# ATSAMS70N19 register map
Vendor: Microchip Technology; File version: 0
CPU: CM7 r1p1, little endian, no MPU, no FPU, 0x3 interrupt priority bits, 0x0 interrupts
Registers are 32-bit, read-write, reset 0x0 unless marked. A register's access mark holds for its fields unless they carry their own. Offsets are from the block's base; [hi:lo] are bit positions; {n}, {i} and the like mark numbered series; 'fields as' and 'values as' point back to an identical list.

## AFEC0 — Analog Front-End Controller
Base 0x4003C000; register names take the prefix AFEC_
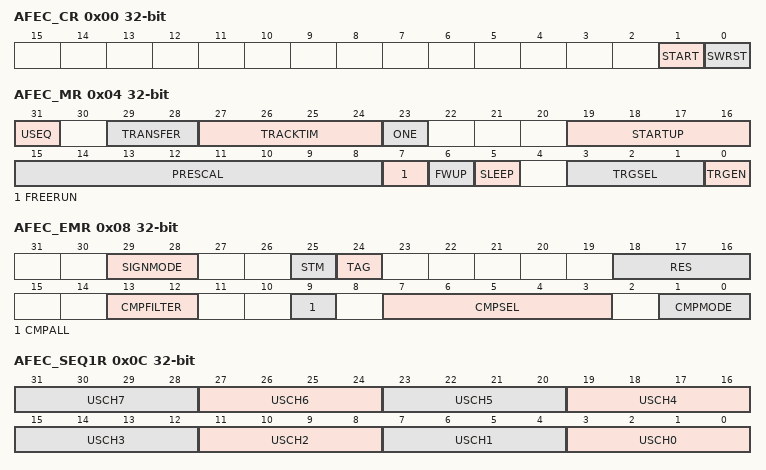
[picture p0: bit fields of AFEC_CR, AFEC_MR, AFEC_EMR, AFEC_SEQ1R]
0x00 AFEC_CR wo — AFEC Control Register
  [1] START — Start Conversion
  [0] SWRST — Software Reset
0x04 AFEC_MR — AFEC Mode Register
  [31] USEQ — User Sequence Enable
    0=NUM_ORDER (Normal mode: The controller converts channels in a simple numeric order.); 1=REG_ORDER (User Sequence mode: The sequence respects what is defined in AFEC_SEQ1R and AFEC_SEQ1R.)
  [29:28] TRANSFER — Transfer Period
  [27:24] TRACKTIM — Tracking Time
  [23] ONE
  [19:16] STARTUP — Start-up Time
    0=SUT0 (0 periods of AFE clock); 1=SUT8 (8 periods of AFE clock); 2=SUT16 (16 periods of AFE clock); 3=SUT24 (24 periods of AFE clock); 4=SUT64 (64 periods of AFE clock); 5=SUT80 (80 periods of AFE clock); 6=SUT96 (96 periods of AFE clock); 7=SUT112 (112 periods of AFE clock); 8=SUT512 (512 periods of AFE clock); 9=SUT576 (576 periods of AFE clock); 10=SUT640 (640 periods of AFE clock); 11=SUT704 (704 periods of AFE clock); 12=SUT768 (768 periods of AFE clock); 13=SUT832 (832 periods of AFE clock); 14=SUT896 (896 periods of AFE clock); 15=SUT960 (960 periods of AFE clock)
  [15:8] PRESCAL — Prescaler Rate Selection
  [7] FREERUN — Free Run Mode
    0=OFF (Normal mode); 1=ON (Free Run mode: Never wait for any trigger.)
  [6] FWUP — Fast Wake-up
    0=OFF (Normal Sleep mode: The sleep mode is defined by the SLEEP bit.); 1=ON (Fast wake-up Sleep mode: The voltage reference is ON between conversions and AFE is OFF.)
  [5] SLEEP — Sleep Mode
    0=NORMAL (Normal mode: The AFE and reference voltage circuitry are kept ON between conversions.); 1=SLEEP (Sleep mode: The AFE and reference voltage circuitry are OFF between conversions.)
  [3:1] TRGSEL — Trigger Selection
    0=AFEC_TRIG0 (AFE0_ADTRG for AFEC0 / AFE1_ADTRG for AFEC1); 1=AFEC_TRIG1 (TIOA Output of the Timer Counter Channel 0 for AFEC0/TIOA Output of the Timer Counter Channel 3 for AFEC1); 2=AFEC_TRIG2 (TIOA Output of the Timer Counter Channel 1 for AFEC0/TIOA Output of the Timer Counter Channel 4 for AFEC1); 3=AFEC_TRIG3 (TIOA Output of the Timer Counter Channel 2 for AFEC0/TIOA Output of the Timer Counter Channel 5 for AFEC1); 4=AFEC_TRIG4 (PWM0 event line 0 for AFEC0 / PWM1 event line 0 for AFEC1); 5=AFEC_TRIG5 (PWM0 event line 1 for AFEC0 / PWM1 event line 1 for AFEC1); 6=AFEC_TRIG6 (Analog Comparator)
  [0] TRGEN — Trigger Enable
    0=DIS (Hardware triggers are disabled. Starting a conversion is only possible by software.); 1=EN (Hardware trigger selected by TRGSEL field is enabled.)
0x08 AFEC_EMR — AFEC Extended Mode Register
  [29:28] SIGNMODE
    0=SE_UNSG_DF_SIGN (Single-Ended channels: Unsigned conversions.Differential channels: Signed conversions.); 1=SE_SIGN_DF_UNSG (Single-Ended channels: Signed conversions.Differential channels: Unsigned conversions.); 2=ALL_UNSIGNED (All channels: Unsigned conversions.); 3=ALL_SIGNED (All channels: Signed conversions.)
  [25] STM — Single Trigger Mode
  [24] TAG — TAG of the AFEC_LDCR
  [18:16] RES — Resolution
    0=NO_AVERAGE (12-bit resolution, AFE sample rate is maximum (no averaging).); 2=OSR4 (13-bit resolution, AFE sample rate divided by 4 (averaging).); 3=OSR16 (14-bit resolution, AFE sample rate divided by 16 (averaging).); 4=OSR64 (15-bit resolution, AFE sample rate divided by 64 (averaging).); 5=OSR256 (16-bit resolution, AFE sample rate divided by 256 (averaging).)
  [13:12] CMPFILTER — Compare Event Filtering
  [9] CMPALL — Compare All Channels
  [7:3] CMPSEL — Comparison Selected Channel
  [1:0] CMPMODE — Comparison Mode
    0=LOW (Generates an event when the converted data is lower than the low threshold of the window.); 1=HIGH (Generates an event when the converted data is higher than the high threshold of the window.); 2=IN (Generates an event when the converted data is in the comparison window.); 3=OUT (Generates an event when the converted data is out of the comparison window.)
0x0C AFEC_SEQ1R — AFEC Channel Sequence 1 Register
  [4n+3:4n] USCH{n} (n=0..7) — User Sequence Number {n}
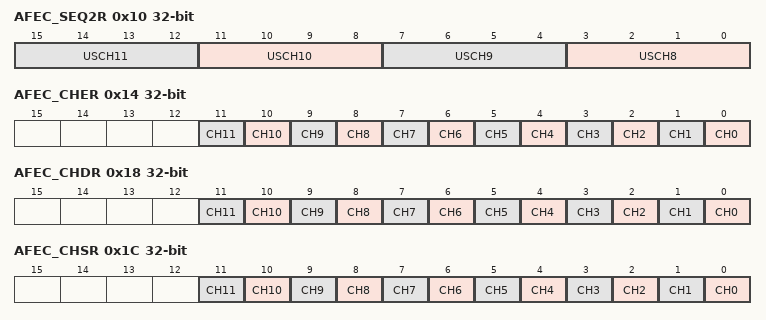
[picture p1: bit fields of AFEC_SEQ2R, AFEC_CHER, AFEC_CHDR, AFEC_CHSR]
0x10 AFEC_SEQ2R — AFEC Channel Sequence 2 Register
  [4n-29:4n-32] USCH{n} (n=8..11) — User Sequence Number {n}
0x14 AFEC_CHER wo — AFEC Channel Enable Register
  [n] CH{n} (n=0..11) — Channel {n} Enable
0x18 AFEC_CHDR wo — AFEC Channel Disable Register
  [n] CH{n} (n=0..11) — Channel {n} Disable
0x1C AFEC_CHSR ro — AFEC Channel Status Register
  [n] CH{n} (n=0..11) — Channel {n} Status
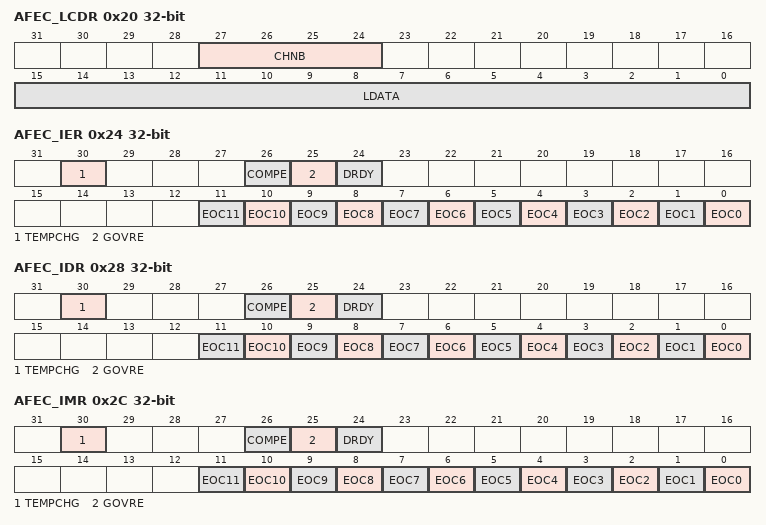
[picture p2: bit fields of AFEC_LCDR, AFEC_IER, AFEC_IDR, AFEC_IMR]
0x20 AFEC_LCDR ro — AFEC Last Converted Data Register
  [27:24] CHNB — Channel Number
  [15:0] LDATA — Last Data Converted
0x24 AFEC_IER wo — AFEC Interrupt Enable Register
  [30] TEMPCHG — Temperature Change Interrupt Enable
  [26] COMPE — Comparison Event Interrupt Enable
  [25] GOVRE — General Overrun Error Interrupt Enable
  [24] DRDY — Data Ready Interrupt Enable
  [n] EOC{n} (n=0..11) — End of Conversion Interrupt Enable {n}
0x28 AFEC_IDR wo — AFEC Interrupt Disable Register
  [30] TEMPCHG — Temperature Change Interrupt Disable
  [26] COMPE — Comparison Event Interrupt Disable
  [25] GOVRE — General Overrun Error Interrupt Disable
  [24] DRDY — Data Ready Interrupt Disable
  [n] EOC{n} (n=0..11) — End of Conversion Interrupt Disable {n}
0x2C AFEC_IMR ro — AFEC Interrupt Mask Register
  [30] TEMPCHG — Temperature Change Interrupt Mask
  [26] COMPE — Comparison Event Interrupt Mask
  [25] GOVRE — General Overrun Error Interrupt Mask
  [24] DRDY — Data Ready Interrupt Mask
  [n] EOC{n} (n=0..11) — End of Conversion Interrupt Mask {n}
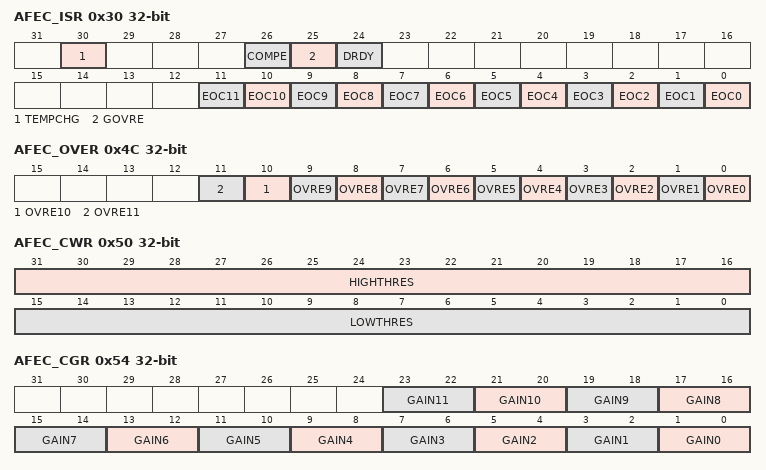
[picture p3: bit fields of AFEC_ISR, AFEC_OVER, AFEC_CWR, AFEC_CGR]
0x30 AFEC_ISR ro — AFEC Interrupt Status Register
  [30] TEMPCHG — Temperature Change (cleared on read)
  [26] COMPE — Comparison Error (cleared by reading AFEC_ISR)
  [25] GOVRE — General Overrun Error (cleared by reading AFEC_ISR)
  [24] DRDY — Data Ready (cleared by reading AFEC_LCDR)
  [n] EOC{n} (n=0..11) — End of Conversion {n} (cleared by reading AFEC_CDRx)
0x4C AFEC_OVER ro — AFEC Overrun Status Register
  [n] OVRE{n} (n=0..11) — Overrun Error {n}
0x50 AFEC_CWR — AFEC Compare Window Register
  [31:16] HIGHTHRES — High Threshold
  [15:0] LOWTHRES — Low Threshold
0x54 AFEC_CGR — AFEC Channel Gain Register
  [2n+1:2n] GAIN{n} (n=0..11) — Gain for Channel {n}
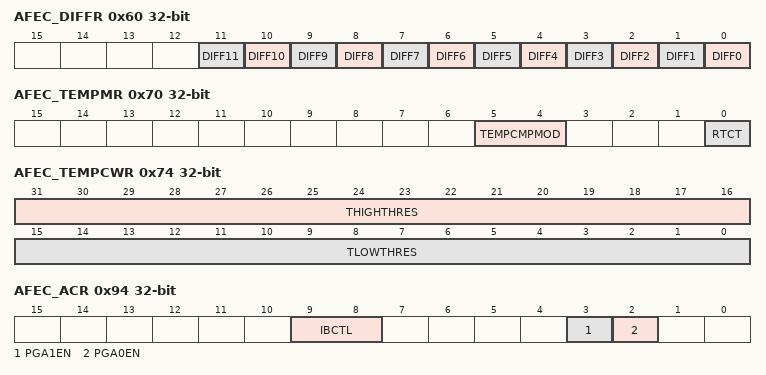
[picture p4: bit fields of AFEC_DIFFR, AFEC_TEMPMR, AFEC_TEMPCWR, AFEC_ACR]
0x60 AFEC_DIFFR — AFEC Channel Differential Register
  [n] DIFF{n} (n=0..11) — Differential inputs for channel {n}
0x64 AFEC_CSELR — AFEC Channel Selection Register
  [3:0] CSEL — Channel Selection
0x68 AFEC_CDR ro — AFEC Channel Data Register
  [15:0] DATA — Converted Data
0x6C AFEC_COCR — AFEC Channel Offset Compensation Register
  [9:0] AOFF — Analog Offset
0x70 AFEC_TEMPMR — AFEC Temperature Sensor Mode Register
  [5:4] TEMPCMPMOD — Temperature Comparison Mode
    values as AFEC_EMR.CMPMODE
  [0] RTCT — Temperature Sensor RTC Trigger Mode
0x74 AFEC_TEMPCWR — AFEC Temperature Compare Window Register
  [31:16] THIGHTHRES — Temperature High Threshold
  [15:0] TLOWTHRES — Temperature Low Threshold
0x94 AFEC_ACR — AFEC Analog Control Register
  [9:8] IBCTL — AFE Bias Current Control
  [3] PGA1EN — PGA1 Enable
  [2] PGA0EN — PGA0 Enable
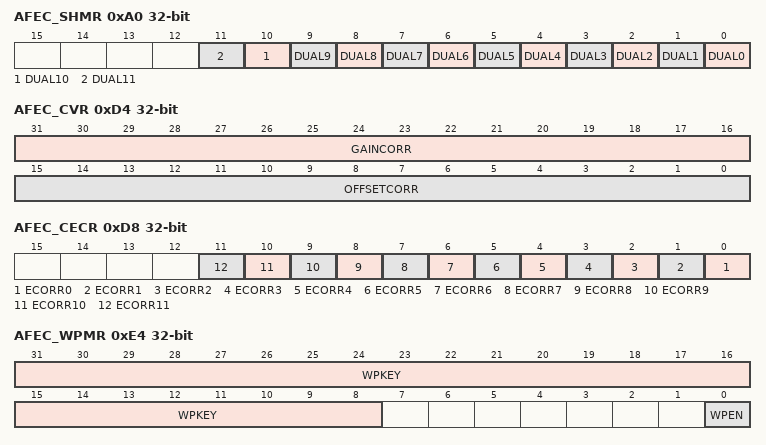
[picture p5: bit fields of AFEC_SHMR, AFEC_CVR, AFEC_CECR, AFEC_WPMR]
0xA0 AFEC_SHMR — AFEC Sample & Hold Mode Register
  [n] DUAL{n} (n=0..11) — Dual Sample & Hold for channel {n}
0xD0 AFEC_COSR — AFEC Correction Select Register
  [0] CSEL — Sample & Hold unit Correction Select
0xD4 AFEC_CVR — AFEC Correction Values Register
  [31:16] GAINCORR — Gain Correction
  [15:0] OFFSETCORR — Offset Correction
0xD8 AFEC_CECR — AFEC Channel Error Correction Register
  [n] ECORR{n} (n=0..11) — Error Correction Enable for channel {n}
0xE4 AFEC_WPMR — AFEC Write Protection Mode Register
  [31:8] WPKEY — Write Protect KEY
    0x414443=PASSWD (Writing any other value in this field aborts the write operation of the WPEN bit. Always reads as 0.)
  [0] WPEN — Write Protection Enable
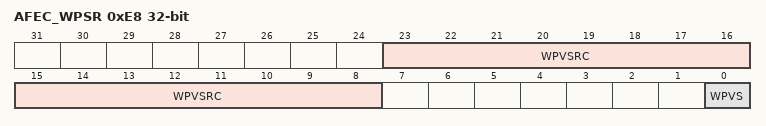
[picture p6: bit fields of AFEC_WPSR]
0xE8 AFEC_WPSR ro — AFEC Write Protection Status Register
  [23:8] WPVSRC — Write Protect Violation Source
  [0] WPVS — Write Protect Violation Status

## AFEC1 — Analog Front-End Controller
Base 0x40064000; register names take the prefix AFEC_
Registers as AFEC0; these are added or differ:
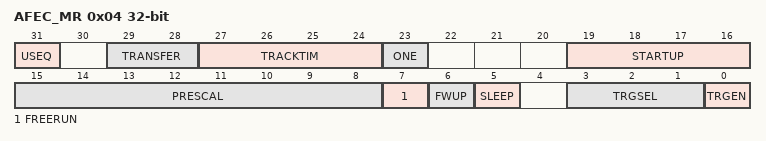
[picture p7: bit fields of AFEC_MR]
0x04 AFEC_MR — AFEC Mode Register
  fields as AFEC0.AFEC_MR
